# IWRL6432 register map
File version: 1.0
CPU: CM4 1.0, other endian, MPU, FPU, 3 interrupt priority bits
Registers are 32-bit, read-write, reset 0x0 unless marked. A register's access mark holds for its fields unless they carry their own. Offsets are from the block's base; [hi:lo] are bit positions; {n}, {i} and the like mark numbered series.

## APP_CTRL (part 2 of 2)
Base 0x56060000
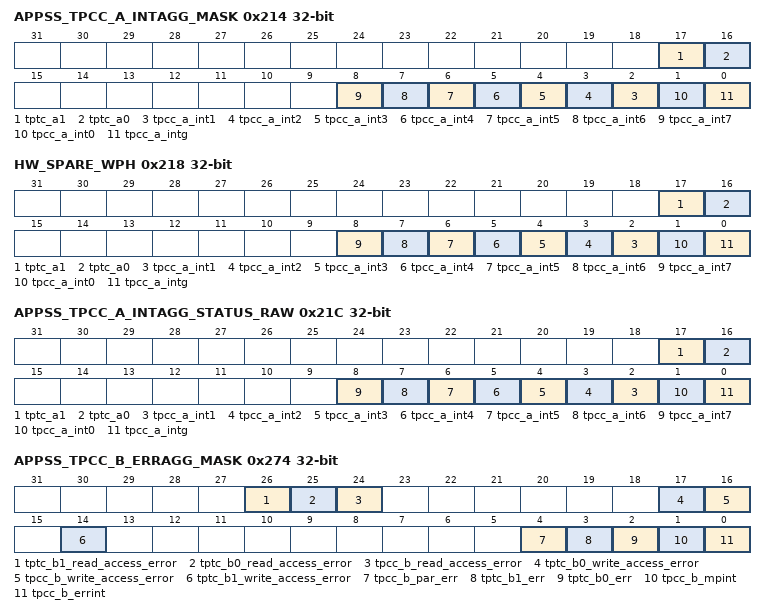
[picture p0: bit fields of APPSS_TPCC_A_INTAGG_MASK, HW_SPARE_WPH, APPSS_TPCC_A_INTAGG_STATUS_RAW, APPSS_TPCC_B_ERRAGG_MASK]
0x214 APPSS_TPCC_A_INTAGG_MASK
  [17] tptc_a1 — [17:17] Mask Interrupt from TPTC A1 to aggregated Interrupt TPCC_A_INTAGG 1 : Interrupt is Masked 0 : Interrupt is Unmasked
  [16] tptc_a0 — [16:16] Mask Interrupt from TPTC A0 to aggregated Interrupt TPCC_A_INTAGG 1 : Interrupt is Masked 0 : Interrupt is Unmasked
  [n+1] tpcc_a_int{n} (n=1..7) — [{n+1}:{n+1}] Mask Interrupt from TPCC_A to aggregated Interrupt TPCC_A_INTAGG 1 : Interrupt is Masked 0 : Interrupt is Unmasked
  [1] tpcc_a_int0 — [1:1] Mask Interrupt from TPCC A to aggregated Interrupt TPCC_A_INTAGG 1 : Interrupt is Masked 0 : Interrupt is Unmasked
  [0] tpcc_a_intg — [0:0] Mask Interrupt from TPCC_A to aggregated Interrupt TPCC_A_INTAGG 1 : Interrupt is Masked 0 : Interrupt is Unmasked
0x218 HW_SPARE_WPH
  [17] tptc_a1 — [17:17] Status of Interrupt from TPTC A1. Set only if Interupt is unmasked in TPCC_A_INTAGG_MASK Wrie 0x1 to clear this interrupt.
  [16] tptc_a0 — [16:16] Status of Interrupt from TPTC A0. Set only if Interupt is unmasked in TPCC_A_INTAGG_MASK Wrie 0x1 to clear this interrupt.
  [n+1] tpcc_a_int{n} (n=1..7) — [{n+1}:{n+1}] Status of Interrupt from TPCC_A. Set only if Interupt is unmasked in TPCC_A_INTAGG_MASK Wrie 0x1 to clear this interrupt.
  [1] tpcc_a_int0 — [1:1] Status of Interrupt from TPCC A Set only if Interupt is unmasked in TPCC_A_INTAGG_MASK Wrie 0x1 to clear this interrupt.
  [0] tpcc_a_intg — [0:0] Status of Interrupt from TPCC_A. Set only if Interupt is unmasked in TPCC_A_INTAGG_MASK Wrie 0x1 to clear this interrupt.
0x21C APPSS_TPCC_A_INTAGG_STATUS_RAW
  [17] tptc_a1 — [17:17] Raw Status of Interrupt from TPTC A1. Set irrespective if the Interupt is masked or unmasked in TPCC_A_INTAGG_MASK
  [16] tptc_a0 — [16:16] Raw Status of Interrupt from TPTC A0. Set irrespective if the Interupt is masked or unmasked in TPCC_A_INTAGG_MASK
  [n+1] tpcc_a_int{n} (n=1..7) — [{n+1}:{n+1}] Raw Status of Interrupt from TPCC_A. Set irrespective if the Interupt is masked or unmasked in TPCC_C_INTAGG_MASK
  [1] tpcc_a_int0 — [1:1] Raw Status of Interrupt from TPCC A. Set irrespective if the Interupt is masked or unmasked in TPCC_A_INTAGG_MASK
  [0] tpcc_a_intg — [0:0] Raw Status of Interrupt from TPCC_A. Set irrespective if the Interupt is masked or unmasked in TPCC_C_INTAGG_MASK
0x274 APPSS_TPCC_B_ERRAGG_MASK
  [26] tptc_b1_read_access_error — [26:26] Mask Error from TPTC_B0 to aggregated Error TPCC_B_ERRAGG 1 : Error is Masked 0 : Error is Unmasked
  [25] tptc_b0_read_access_error — [25:25] Mask Error from TPTC_B0 to aggregated Error TPCC_B_ERRAGG 1 : Error is Masked 0 : Error is Unmasked
  [24] tpcc_b_read_access_error — [24:24] Mask Error from TPCC_B to aggregated Error TPCC_B_ERRAGG 1 : Error is Masked 0 : Error is Unmasked
  [17] tptc_b0_write_access_error — [17:17] Mask Error from TPTC_B0 to aggregated Error TPCC_B_ERRAGG 1 : Error is Masked 0 : Error is Unmasked
  [16] tpcc_b_write_access_error — [16:16] Mask Error from TPCC_B to aggregated Error TPCC_B_ERRAGG 1 : Error is Masked 0 : Error is Unmasked
  [14] tptc_b1_write_access_error — [14:14] Mask Error from TPTC_B0 to aggregated Error TPCC_B_ERRAGG 1 : Error is Masked 0 : Error is Unmasked
  [4] tpcc_b_par_err — [4:4] Mask Error from TPCC_B to aggregated Error TPCC_B_ERRAGG 1 : Error is Masked 0 : Error is Unmasked
  [3] tptc_b1_err — [3:3] Mask Error from TPTC_B0 to aggregated Error TPCC_B_ERRAGG 1 : Error is Masked 0 : Error is Unmasked
  [2] tptc_b0_err — [2:2] Mask Error from TPTC_B0 to aggregated Error TPCC_B_ERRAGG 1 : Error is Masked 0 : Error is Unmasked
  [1] tpcc_b_mpint — [1:1] Mask Error from TPCC_B to aggregated Error TPCC_B_ERRAGG 1 : Error is Masked 0 : Error is Unmasked
  [0] tpcc_b_errint — [0:0] Mask Error from TPCC_B to aggregated Error TPCC_B_ERRAGG 1 : Error is Masked 0 : Error is Unmasked
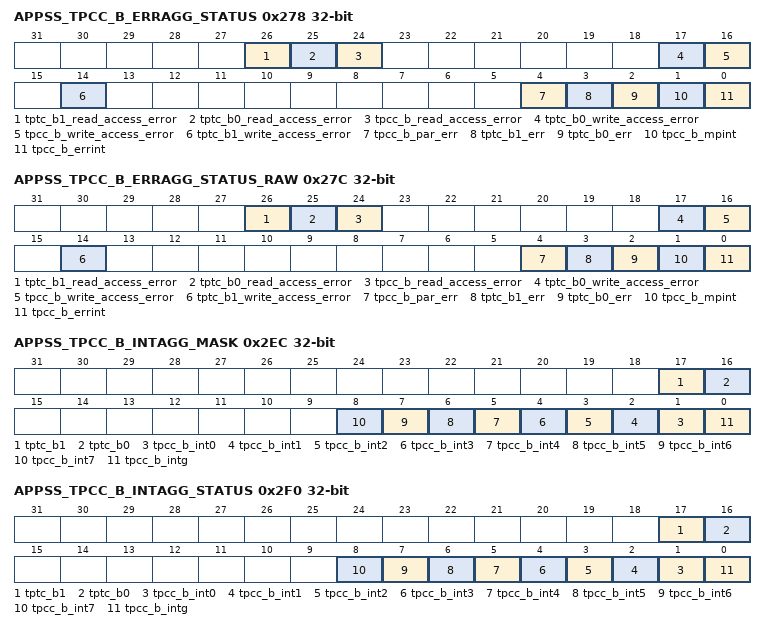
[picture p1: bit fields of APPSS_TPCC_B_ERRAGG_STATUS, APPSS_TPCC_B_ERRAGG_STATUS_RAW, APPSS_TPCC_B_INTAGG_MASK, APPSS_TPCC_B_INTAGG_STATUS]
0x278 APPSS_TPCC_B_ERRAGG_STATUS
  [26] tptc_b1_read_access_error — [26:26] Status of Error from TPTC_B0. Set only if Interupt is unmasked in TPCC_B_ERRAGG_MASK Wrie 0x1 to clear this Error.
  [25] tptc_b0_read_access_error — [25:25] Status of Error from TPTC_B0. Set only if Interupt is unmasked in TPCC_B_ERRAGG_MASK Wrie 0x1 to clear this Error.
  [24] tpcc_b_read_access_error — [24:24] Status of Error from TPCC_B. Set only if Interupt is unmasked in TPCC_B_ERRAGG_MASK Wrie 0x1 to clear this Error.
  [17] tptc_b0_write_access_error — [17:17] Status of Error from TPTC_B0. Set only if Interupt is unmasked in TPCC_B_ERRAGG_MASK Wrie 0x1 to clear this Error.
  [16] tpcc_b_write_access_error — [16:16] Status of Error from TPCC_B. Set only if Interupt is unmasked in TPCC_B_ERRAGG_MASK Wrie 0x1 to clear this Error.
  [14] tptc_b1_write_access_error — [14:14] Status of Error from TPTC_B0. Set only if Interupt is unmasked in TPCC_B_ERRAGG_MASK Wrie 0x1 to clear this Error.
  [4] tpcc_b_par_err — [4:4] Status of Error from TPCC_B. Set only if Interupt is unmasked in TPCC_B_ERRAGG_MASK Wrie 0x1 to clear this Error.
  [3] tptc_b1_err — [3:3] Status of Error from TPTC_B0. Set only if Interupt is unmasked in TPCC_B_ERRAGG_MASK Wrie 0x1 to clear this Error.
  [2] tptc_b0_err — [2:2] Status of Error from TPTC_B0. Set only if Interupt is unmasked in TPCC_B_ERRAGG_MASK Wrie 0x1 to clear this Error.
  [1] tpcc_b_mpint — [1:1] Status of Error from TPCC_B. Set only if Interupt is unmasked in TPCC_B_ERRAGG_MASK Wrie 0x1 to clear this Error.
  [0] tpcc_b_errint — [0:0] Status of Error from TPCC_B. Set only if Interupt is unmasked in TPCC_B_ERRAGG_MASK Wrie 0x1 to clear this Error.
0x27C APPSS_TPCC_B_ERRAGG_STATUS_RAW
  [26] tptc_b1_read_access_error — [26:26] Raw Status of Error from TPTC_B0. Set irrespective if the Interupt is masked or unmasked in TPCC_B_ERRAGG_MASK
  [25] tptc_b0_read_access_error — [25:25] Raw Status of Error from TPTC_B0. Set irrespective if the Interupt is masked or unmasked in TPCC_B_ERRAGG_MASK
  [24] tpcc_b_read_access_error — [24:24] Raw Status of Error from TPCC_B. Set irrespective if the Interupt is masked or unmasked in TPCC_B_ERRAGG_MASK
  [17] tptc_b0_write_access_error — [17:17] Raw Status of Error from TPTC_B0. Set irrespective if the Interupt is masked or unmasked in TPCC_B_ERRAGG_MASK
  [16] tpcc_b_write_access_error — [16:16] Raw Status of Error from TPCC_B. Set irrespective if the Interupt is masked or unmasked in TPCC_B_ERRAGG_MASK
  [14] tptc_b1_write_access_error — [14:14] Raw Status of Error from TPTC_B0. Set irrespective if the Interupt is masked or unmasked in TPCC_B_ERRAGG_MASK
  [4] tpcc_b_par_err — [4:4] Raw Status of Error from TPCC_B. Set irrespective if the Interupt is masked or unmasked in TPCC_B_ERRAGG_MASK
  [3] tptc_b1_err — [3:3] Raw Status of Error from TPTC_B0. Set irrespective if the Interupt is masked or unmasked in TPCC_B_ERRAGG_MASK
  [2] tptc_b0_err — [2:2] Raw Status of Error from TPTC_B0. Set irrespective if the Interupt is masked or unmasked in TPCC_B_ERRAGG_MASK
  [1] tpcc_b_mpint — [1:1] Raw Status of Error from TPCC_B. Set irrespective if the Interupt is masked or unmasked in TPCC_B_ERRAGG_MASK
  [0] tpcc_b_errint — [0:0] Raw Status of Error from TPCC_B. Set irrespective if the Interupt is masked or unmasked in TPCC_B_ERRAGG_MASK
0x2EC APPSS_TPCC_B_INTAGG_MASK
  [17] tptc_b1 — [17:17] Mask Interrupt from TPTC A0 to aggregated Interrupt TPCC_A_INTAGG 1 : Interrupt is Masked 0 : Interrupt is Unmasked
  [16] tptc_b0 — [16:16] Mask Interrupt from TPTC A0 to aggregated Interrupt TPCC_A_INTAGG 1 : Interrupt is Masked 0 : Interrupt is Unmasked
  [n+1] tpcc_b_int{n} (n=0..7) — [{n+1}:{n+1}] Mask Interrupt from TPCC_B to aggregated Interrupt TPCC_B_INTAGG 1 : Interrupt is Masked 0 : Interrupt is Unmasked
  [0] tpcc_b_intg — [0:0] Mask Interrupt from TPCC_B to aggregated Interrupt TPCC_B_INTAGG 1 : Interrupt is Masked 0 : Interrupt is Unmasked
0x2F0 APPSS_TPCC_B_INTAGG_STATUS
  [17] tptc_b1 — [17:17] Status of Interrupt from TPTC A0. Set only if Interupt is unmasked in TPCC_A_INTAGG_MASK Wrie 0x1 to clear this interrupt.
  [16] tptc_b0 — [16:16] Status of Interrupt from TPTC A0. Set only if Interupt is unmasked in TPCC_A_INTAGG_MASK Wrie 0x1 to clear this interrupt.
  [n+1] tpcc_b_int{n} (n=0..7) — [{n+1}:{n+1}] Status of Interrupt from TPCC_B. Set only if Interupt is unmasked in TPCC_B_INTAGG_MASK Wrie 0x1 to clear this interrupt.
  [0] tpcc_b_intg — [0:0] Status of Interrupt from TPCC_B. Set only if Interupt is unmasked in TPCC_B_INTAGG_MASK Wrie 0x1 to clear this interrupt.
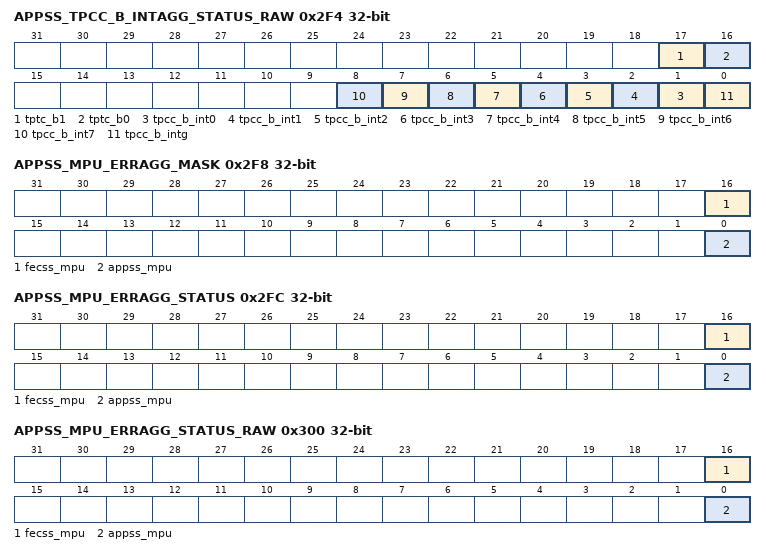
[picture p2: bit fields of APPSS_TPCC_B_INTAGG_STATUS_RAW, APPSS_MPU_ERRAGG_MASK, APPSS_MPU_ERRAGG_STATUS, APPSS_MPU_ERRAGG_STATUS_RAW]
0x2F4 APPSS_TPCC_B_INTAGG_STATUS_RAW
  [17] tptc_b1 — [17:17] Raw Status of Interrupt from TPTC A0. Set irrespective if the Interupt is masked or unmasked in TPCC_A_INTAGG_MASK
  [16] tptc_b0 — [16:16] Raw Status of Interrupt from TPTC A0. Set irrespective if the Interupt is masked or unmasked in TPCC_A_INTAGG_MASK
  [n+1] tpcc_b_int{n} (n=0..7) — [{n+1}:{n+1}] Raw Status of Interrupt from TPCC_B. Set irrespective if the Interupt is masked or unmasked in TPCC_C_INTAGG_MASK
  [0] tpcc_b_intg — [0:0] Raw Status of Interrupt from TPCC_B. Set irrespective if the Interupt is masked or unmasked in TPCC_C_INTAGG_MASK
0x2F8 APPSS_MPU_ERRAGG_MASK
  [16] fecss_mpu — [16:16] Mask Interrupt from FECSS MPU to aggregated Interrupt MPU_PROT_AGG_ERR 1 : Interrupt is Masked 0 : Interrupt is Unmasked
  [0] appss_mpu — [0:0] Mask Interrupt from APSS MPU to aggregated Interrupt MPU_PROT_AGG_ERR 1 : Interrupt is Masked 0 : Interrupt is Unmasked
0x2FC APPSS_MPU_ERRAGG_STATUS
  [16] fecss_mpu — [16:16] Status of Interrupt from FECSS MPU. Set only if Interupt is unmasked in APPSS_MPU_ERRAGG_MASK Wrie 0x1 to clear this interrupt.
  [0] appss_mpu — [0:0] Status of Interrupt from APSS MPU. Set only if Interupt is unmasked in APPSS_MPU_ERRAGG_MASK Wrie 0x1 to clear this interrupt.
0x300 APPSS_MPU_ERRAGG_STATUS_RAW
  [16] fecss_mpu — [16:16] Raw Status of FECSS MPU PROT ERR. Set irrespective if the Interupt is masked or unmasked in APPSS_MPU_ERRAGG_MASK
  [0] appss_mpu — [0:0] Raw Status of Interrupt from APSS MPU PROT ERR Set irrespective if the Interupt is masked or unmasked in APPSS_MPU_ERRAGG_MASK
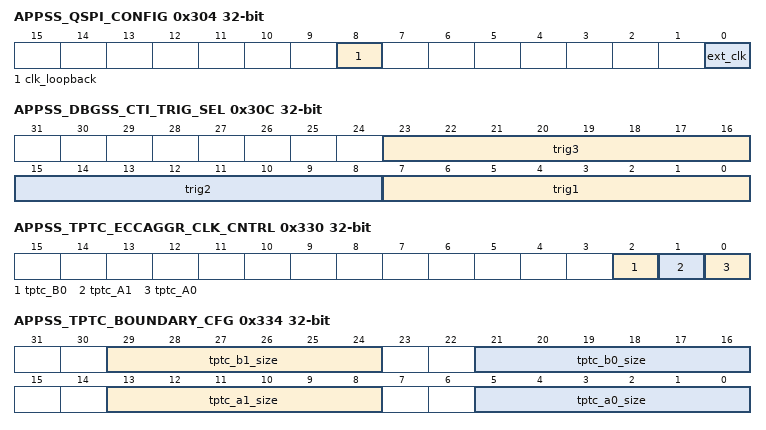
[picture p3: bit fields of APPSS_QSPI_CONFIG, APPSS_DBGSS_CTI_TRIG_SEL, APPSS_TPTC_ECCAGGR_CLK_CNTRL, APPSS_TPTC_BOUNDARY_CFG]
0x304 APPSS_QSPI_CONFIG
  [8] clk_loopback — [8:8] Reserved
  [0] ext_clk — [0:0] Reserved
0x308 APPSS_CTI_TRIG_SEL
  [7:0] trig8_sel — [7:0] Used for selecting the trigger source for 8th trigger of CTI
0x30C APPSS_DBGSS_CTI_TRIG_SEL
  [23:16] trig3 — [23:16] Reserved
  [15:8] trig2 — [15:8] Reserved
  [7:0] trig1 — [7:0] Reserved
{0x310+4i} APPSS_BOOT_INFO_REG{i} (i=0..7)
  [31:0] config — [31:0] Reserved Register for Software use
0x330 APPSS_TPTC_ECCAGGR_CLK_CNTRL
  [2] tptc_B0 — [2:2] Writing '0' will gate the clock to TPTC_B0-FIFO during ECC-AGGR interaction(fault injection)
  [1] tptc_A1 — [1:1] Writing '0' will gate the clock to TPTC_A1-FIFO during ECC-AGGR interaction(fault injection)
  [0] tptc_A0 — [0:0] Writing '0' will gate the clock to TPTC_A0-FIFO during ECC-AGGR interaction(fault injection)
0x334 APPSS_TPTC_BOUNDARY_CFG
  [29:24] tptc_b1_size — [29:24] 6 bit signal used for deciding the boundary crossing size for CID-RID-SID reordering of TPTC_B1 Example: writing 6'd19 decidies boundary to be 2^19 i.e. 512 KB
  [21:16] tptc_b0_size — [21:16] 6 bit signal used for deciding the boundary crossing size for CID-RID-SID reordering of TPTC_B0 Example: writing 6'd19 decidies boundary to be 2^19 i.e. 512 KB
  [13:8] tptc_a1_size — [13:8] 6 bit signal used for deciding the boundary crossing size for CID-RID-SID reordering of TPTC_A1 Example: writing 6'd19 decidies boundary to be 2^19 i.e. 512 KB
  [5:0] tptc_a0_size — [5:0] 6 bit signal used for deciding the boundary crossing size for CID-RID-SID reordering of TPTC_A0 Example: writing 6'd19 decidies boundary to be 2^19 i.e. 512 KB
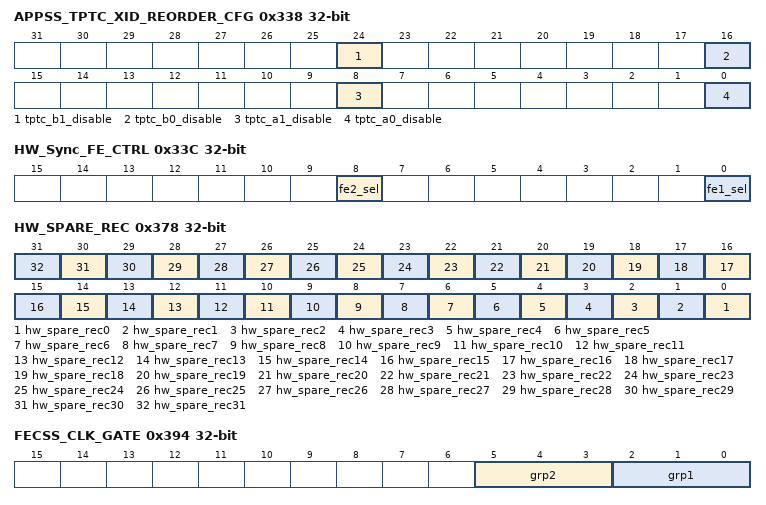
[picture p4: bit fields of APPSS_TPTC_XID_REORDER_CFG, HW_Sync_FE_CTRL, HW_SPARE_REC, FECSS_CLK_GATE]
0x338 APPSS_TPTC_XID_REORDER_CFG
  [24] tptc_b1_disable — [24:24] writing 1'b1 will disable the CID-RID-SID reodering feature for TPTC_B1
  [16] tptc_b0_disable — [16:16] writing 1'b1 will disable the CID-RID-SID reodering feature for TPTC_B0
  [8] tptc_a1_disable — [8:8] writing 1'b1 will disable the CID-RID-SID reodering feature for TPTC_A1
  [0] tptc_a0_disable — [0:0] writing 1'b1 will disable the CID-RID-SID reodering feature for TPTC_A0
0x33C HW_Sync_FE_CTRL
  [8] fe2_sel — [8:8] RESERVED
  [0] fe1_sel — [0:0] RESERVED
{0x33C+4i} HW_SPARE_REG{i} (i=1..3)
  [31:0] NU — [31:0] Resereved for R&D
0x34C NERROR_MASK
  [0] mask — [0:0] writing 1'b1 will mask the Nerror propagation to pad Writing 1'b0 will unmask the Nerror propagation to pad
0x350 HW_SPARE_RW0
  [31:0] hw_spare_rw0 — [31:0] Bit 0: Writing 1'b1 will mask the hwa local ram agg serr propagation to ESM Writing 1'b0 will unmask the hwa local ram agg serr propagation to ESM Bit 1 : Writing 1'b1 will mask the hwa local ram agg uerr propagation to ESM Writing 1'b0 will unmask the hwa local ram agg uerr propagation to ESM Bit 2 to 31 Reserved
{0x350+4i} HW_SPARE_RW{i} (i=1..5)
  [31:0] hw_spare_rw{i} — [31:0] Reserved for HW R&D
{0x368+4i} HW_SPARE_RO{i} (i=0..3)
  [31:0] hw_spare_ro{i} — [31:0] Reserved for HW R&D
0x378 HW_SPARE_REC
  [n] hw_spare_rec{n} (n=0..31) — [{n}:{n}] Reserved for HW R&D
0x37C APP_CTRL
  [0] ecc_disable_2k_ram — [0:0] Reserved
0x380 WIC_CTRL
  [31:0] wicmask — [31:0] 1 => The corresponding interrupt is Masked (interrupt will not be generated) 0 => The corresponding interrupt is UnMasked (interrupt will be generated) 0 : ESM_HI_IRQ (NMI) 1 : ESM_LO_IRQ (INT#1) 2 : FECSS_FRAMETIMER_FRAME_START (INT#33) 3 : MUXED_FECSS_FRAME_START_OFFSET_INTR_TIME1 (INT#35) 4 : FECSS_FRAME_START_OFFSET_INTR_TIME2 (INT#36) 5 : FECSS_FRAME_START_OFFSET_INTR_TIME3 (INT#37) 6 : FECSS_BURST_START_OFFSET_TIME(INT#38) 7 : MUXED_APPSS_RTI1_RTI2_INT_REQ0(INT#43) 8 : MUXED_APPSS_RTI1_RTI2_INT_REQ1(INT#44) 9 : MUXED_APPSS_RTI1_RTI2_INT_REQ2(INT#45) 10 : MUXED_APPSS_RTI1_RTI2_INT_REQ3(INT#46) 11 : APPSS_SPI_IRQ_REQ(INT#14) 12 : SPI2_IRQ_REQ (part of INT#28) 13 : APPSS_LIN_INT0 (INT#10) 14 : APPSS_LIN_INT0 (INT#11) 15 : APPSS_MCAN_INT0(INT#21) 16 : APPSS_MCAN_INT1(INT#22) 17 : APPSS_SCI2_INT0(INT#62) 18 : APPSS_SCI2_INT0(INT#63) 19 : APPSS_SPI_IRQ_REQ(INT#14) 20 : SPI2_IRQ_REQ (part of INT#28) 21 : APPSS_LIN_INT0 (INT#10) 22 : APPSS_LIN_INT0 (INT#11) 23 : APPSS_MCAN_INT0(INT#21) 24 : APPSS_MCAN_INT1(INT#22) 25 : APPSS_SCI2_INT0(INT#62) 26 : APPSS_SCI2_INT0(INT#63) 27 : SYNC_IN 28 : RADAR_DEVICESLEEP_WAKEUP_INTERRUPT 29 to 31 : Reserved
0x384 WIC_STAT_CLR
  [31:0] wicstatclr — [31:0] 1 => Writing 1 to this bit, will clear the WIC_STAT status register of the corresponding bit. Self-clearing 0 => Writing 0 to this bit, leavesWIC_STAT status register unchanged for the corresponding bit.
0x388 WIC_STAT
  [31:0] wicstat — [31:0] 1 => Interrupt bit set. The interupt bit is sticky bit. Should be cleared using WIC_STAT_CLR register or subsystem reset. 0 -> Interrupt bit not set. Sticky bits keep their value when they changed to logical 1 and is cleared only by writing 1 to WIC_STAT_CLR register.
0x38C WICEN
  [0] wicen — [0:0] 1 :> Wakeup Interrupt Controller (WIC) of CM4 is Enabled 0 :> Disabled
0x390 FORCEFCLKACTIVE
  [0] forcefclkactive — [0:0] 1 :> Forces FCLK to be active and inhibits CM4 Entering CPU DeepSleep mode 0 :> Allows gating of FCLK based on CPU DEEPSLEEP entry mechanism
0x394 FECSS_CLK_GATE
  [5:3] grp2 — [5:3] Multibit: Writing 3'b111 will gate ADC_CLK going to DFE and Timing Engine
  [2:0] grp1 — [2:0] Multibit: Writing 3'b111 will gate FEC_SYS_CLK and FECSS peripheral clocks except DFE and Timing Engine
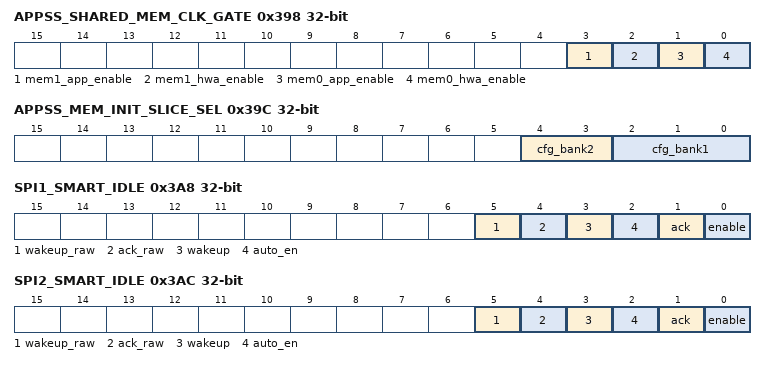
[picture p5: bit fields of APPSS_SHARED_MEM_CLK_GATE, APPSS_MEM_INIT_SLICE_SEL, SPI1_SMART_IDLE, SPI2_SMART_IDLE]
0x398 APPSS_SHARED_MEM_CLK_GATE
  [3] mem1_app_enable — [3:3] 1'b1 : Enable APP CLK ICG for second 128KB of shared mem 1'b0 : Disable APP CLK ICG for second 128 KB of shared mem
  [2] mem1_hwa_enable — [2:2] 1'b1 : Enable HWA CLK ICG for second 128 KB of shared mem 1'b0 : Disable HWA CLK ICG for second 128 KB of shared mem
  [1] mem0_app_enable — [1:1] 1'b1 : Enable APP CLK ICG for first 128KB of shared mem 1'b0 : Disable APP CLK ICG for first 128 KB of shared mem
  [0] mem0_hwa_enable — [0:0] 1'b1 : Enable HWA CLK ICG for first 128 KB of shared mem 1'b0 : Disable HWA CLK ICG for first 128 KB of shared mem
0x39C APPSS_MEM_INIT_SLICE_SEL
  [4:3] cfg_bank2 — [4:3] Selects the APPSS RAM2 partition that needs to be initialized. More than 1 partitions can be selected for mem_init. Bit#0 : Selects RAM_2A (16KB) Bit#1 : Selects RAM_2B (112KB) 1 => RAM partition selected for mem_init operation 0 => RAM partition not selected for mem_init operation.
  [2:0] cfg_bank1 — [2:0] Selects the APPSS RAM1 partition that needs to be initialized. More than 1 partitions can be selected for mem_init. Bit#0 : Selects RAM_1A (64KB) Bit#1 : Selects RAM_1B (64KB) Bit#2 : Selects RAM_1C (128KB) 1 => RAM selected for mem_init operation 0 => RAM not selected for mem_init operation.
0x3A0 APPSS_QSPI_CHAR_EXT_CLK_EN
  [0] enable — [0:0] Selects the QSPI system clock. Only for DFT purposes. This should not be changed for functional operation. 0 => QSPI_CLK from APPSS RCM 1 => SPI1_CLK from APPSS RCM
0x3A4 APPSS_QSPI_EXT_CLK_EN
  [0] enable — [0:0] Selects the QSPI interface clock. This register bit is used only for AC CHAR operation and not for functional usage. 0 => default QSPI IP clock return from PAD 1 => SPI1 IF CLK. (McSPI IF clock).
0x3A8 SPI1_SMART_IDLE
  [5] wakeup_raw — [5:5] Description: RAW status of CLKSTOP_WAKEUP from SPI1 module. This should be interpreted along with SPI1_SMART_IDLE_WAKEUP SPI1_SMART_IDLE_WAKEUP_RAW, SPI1_SMART_IDLE_WAKEUP 0 , 0 => WAKEUP is LOW from IP, and No pending WAKEUP status 0 , 1 => WAKEUP is LOW from IP, and pending WAKEUP status 1 , 0 => WAKEUP is HIGH from IP, and No pending WAKEUP status 1 , 1 => WAKEUP is HIGH from IP, and pending WAKEUP status
  [4] ack_raw — [4:4] Description: RAW status of CLKSTOP_ACK from McSPI (SPI1) module. This should be interpreted along with SPI1_SMART_IDLE_ACK SPI1_SMART_IDLE_ACK_RAW, SPI1_SMART_IDLE_ACK 0 , 0 => ACK is LOW from IP, and No pending ACK status 0 , 1 => ACK is LOW from IP, and pending ACK status 1 , 0 => ACK is HIGH from IP, and No pending ACK status 1 , 1 => ACK is HIGH from IP, and pending ACK status
  [3] wakeup — [3:3] This register reflects the Wakeup Status of the IP. The bit is sticky bit and the user is should clear once the status is read by write-1-to-clear.
  [2] auto_en — [2:2] It is used to select smart idle mode. 1 => Automatic mode - Entry to smart idle mode Is manual by setting SMART_IDLE_ENABLE = 1. When the wakeup Signal is asserted (based on the activity), The clkstop_req is pulled low automatically. 0 => Manual mode - The entry and exit to Smart Idle is user controlled based on polling SMART_IDLE_ACK and SMART_IDLE_WAKEUP
  [1] ack — [1:1] 1 => SPI1 in smart idle mode 0 => SPI1 not in smart idle mode The bit is sticky bit and the user is should clear once the status is read by write-1-to-clear.
  [0] enable — [0:0] 1 => Smart IDLE mode enabled. When set, request the clock gating of SPI1 module. 0 => Disable Smart IDLE mode for SPI1
0x3AC SPI2_SMART_IDLE
  [5] wakeup_raw — [5:5] Description: RAW status of CLKSTOP_WAKEUP from SPI2 module. This should be interpreted along with SPI2_SMART_IDLE_WAKEUP SPI2_SMART_IDLE_WAKEUP_RAW, SPI2_SMART_IDLE_WAKEUP 0 , 0 => WAKEUP is LOW from IP, and No pending WAKEUP status 0 , 1 => WAKEUP is LOW from IP, and pending WAKEUP status 1 , 0 => WAKEUP is HIGH from IP, and No pending WAKEUP status 1 , 1 => WAKEUP is HIGH from IP, and pending WAKEUP status
  [4] ack_raw — [4:4] Description: RAW status of CLKSTOP_ACK from McSPI (SPI2) module. This should be interpreted along with SPI2_SMART_IDLE_ACK SPI2_SMART_IDLE_ACK_RAW, SPI2_SMART_IDLE_ACK 0 , 0 => ACK is LOW from IP, and No pending ACK status 0 , 1 => ACK is LOW from IP, and pending ACK status 1 , 0 => ACK is HIGH from IP, and No pending ACK status 1 , 1 => ACK is HIGH from IP, and pending ACK status
  [3] wakeup — [3:3] This register reflects the Wakeup Status of the IP. The bit is sticky bit and the user is should clear once the status is read by write-1-to-clear.
  [2] auto_en — [2:2] It is used to select smart idle mode. 1 => Automatic mode - In this mode, entry to smart idle mode is manual by setting SMART_IDLE_ENABLE = 1. When the wakeup Signal is asserted (based on the activity), The clkstop_req is pulled low automatically. 0 => Manual mode - The entry and exit to Smart Idle is user controlled based on polling SMART_IDLE_ACK and SMART_IDLE_WAKEUP
  [1] ack — [1:1] 1 => SPI2 in smart idle mode 0 => SPI2 not in smart idle mode The bit is sticky bit and the user is should clear once the status is read by write-1-to-clear.
  [0] enable — [0:0] 1 => Smart IDLE mode enabled. When set, request the clock gating of SPI2 module. 0 => Disable Smart IDLE mode for SPI2
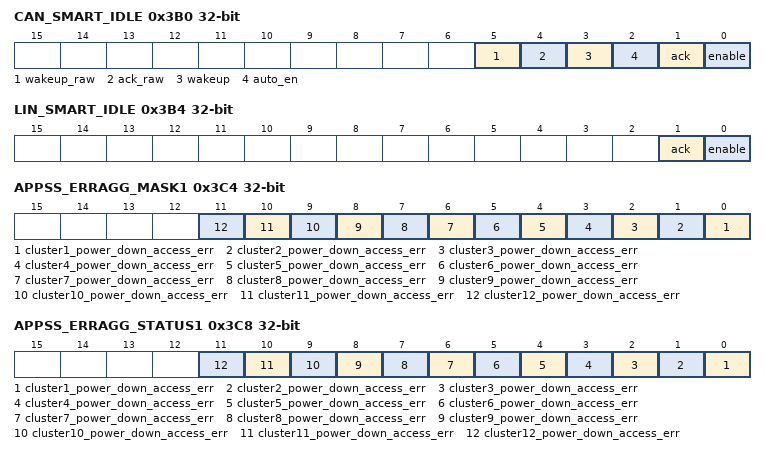
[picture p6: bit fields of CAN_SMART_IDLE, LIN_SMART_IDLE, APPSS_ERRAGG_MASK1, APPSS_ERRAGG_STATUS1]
0x3B0 CAN_SMART_IDLE
  [5] wakeup_raw — [5:5] Description: RAW status of CLKSTOP_WAKEUP from CANFD module. This should be interpreted along with CAN_SMART_IDLE_WAKEUP CAN_SMART_IDLE_WAKEUP_RAW, CAN_SMART_IDLE_WAKEUP 0 , 0 => WAKEUP is LOW from IP, and No pending WAKEUP status 0 , 1 => WAKEUP is LOW from IP, and pending WAKEUP status 1 , 0 => WAKEUP is HIGH from IP, and No pending WAKEUP status 1 , 1 => WAKEUP is HIGH from IP, and pending WAKEUP status
  [4] ack_raw — [4:4] Description: RAW status of CLKSTOP_ACK from CANFD module. This should be interpreted along with CAN_SMART_IDLE_ACK CAN_SMART_IDLE_ACK_RAW, CAN_SMART_IDLE_ACK 0 , 0 => ACK is LOW from IP, and No pending ACK status 0 , 1 => ACK is LOW from IP, and pending ACK status 1 , 0 => ACK is HIGH from IP, and No pending ACK status 1 , 1 => ACK is HIGH from IP, and pending ACK status
  [3] wakeup — [3:3] This register reflects the Wakeup Status of the IP. The bit is sticky bit and the user is should clear once the status is read by write-1-to-clear.
  [2] auto_en — [2:2] It is used to select smart idle mode. 1 => Automatic mode - In this mode, entry to smart idle mode is manual by setting SMART_IDLE_ENABLE = 1. When the wakeup Signal is asserted (based on the activity), The clkstop_req is pulled low automatically. 0 => Manual mode - The entry and exit to Smart Idle is user controlled based on polling SMART_IDLE_ACK and SMART_IDLE_WAKEUP
  [1] ack — [1:1] 1 => CAN in smart idle mode0 => CAN not in smart idle mode The bit is sticky bit and the user is should clear once the status is read by write-1-to-clear.
  [0] enable — [0:0] 1 => Smart IDLE mode enabled. When set, Request the clock gating of CAN module.0 => Disable Smart IDLE mode for CAN
0x3B4 LIN_SMART_IDLE
  [1] ack — [1:1] 1 => LIN in smart idle mode0 => LIN not in smart idle mode
  [0] enable — [0:0] 1 => Smart IDLE mode enabled. When set, Request the clock gating of LIN module.0 => Disable Smart IDLE mode for LIN
0x3B8 HWASS_CLK_GATE
  [2:0] enable — [2:0] RESERVED
0x3BC CFG_TIMEOUT_PCR3
  [31:0] value — [31:0] PCR3Timeout Value
0x3C4 APPSS_ERRAGG_MASK1
  [n-1] cluster{n}_power_down_access_err (n=1..12) — [{n-1}:{n-1}] Mask Interrupt from cluster{n}_power_down_access_err Interrupt APPSS_ACCESS_ERRAGG 1 : Interrupt is Masked 0 : Interrupt is Unmasked
0x3C8 APPSS_ERRAGG_STATUS1
  [n-1] cluster{n}_power_down_access_err (n=1..12) — [{n-1}:{n-1}] Status of Interrupt from cluster{n}_power_down_access_err Set only if Interupt is unmasked in APPSS_ERRAGG_MASK1 Wrie 0x1 to clear this interrupt.
0x3CC FORCEHCLKACTIVE
  [0] forcehclkactive — [0:0] 1 :> Gate HCLK 0 :> UnGate HCLK
{0x3C8+8i} APPSS_RAM{i}_OWRITE_ERR (i=1..3)
  [0] err — [0:0] RAM{i} ahb2sram write error - Sticky Bit
{0x3CC+8i} APPSS_RAM{i}_OWRITE_ERR_ADDR (i=1..3)
  [31:0] address — [31:0] RAM{i} ahb2sram write error Address
0x3E8 APPSS_SHRD_RAM_OWRITE_ERR
  [0] err — [0:0] SHARED RAM ahb2sram write error - Sticky Bit
0x3EC APPSS_SHRD_RAM_OWRITE_ERR_ADDR
  [31:0] address — [31:0] SHARED RAM ahb2sram write error Address
0x3F0 APPSS_OWRITE_ERR_AGGR
  [0] err — [0:0] Ored error of all write error signals -Sticky Bit
{0x3DC+4i} HW_SPARE_RW{i} (i=6..9)
  [31:0] hw_spare_rw{i} — [31:0] Reserved for HW R&D
0x404 HW_SPARE_HWA_RW0
  [31:0] hw_spare_hwa_rw0 — [31:0] Reserved for HW R&D
0x1008 LOCK0_KICK0 — - KICK0 component
  [31:0] KICK0_COMPONENT — [31:0] - KICK0 component
0x100C LOCK0_KICK1 — - KICK1 component
  [31:0] KICK1_COMPONENT — [31:0] - KICK1 component
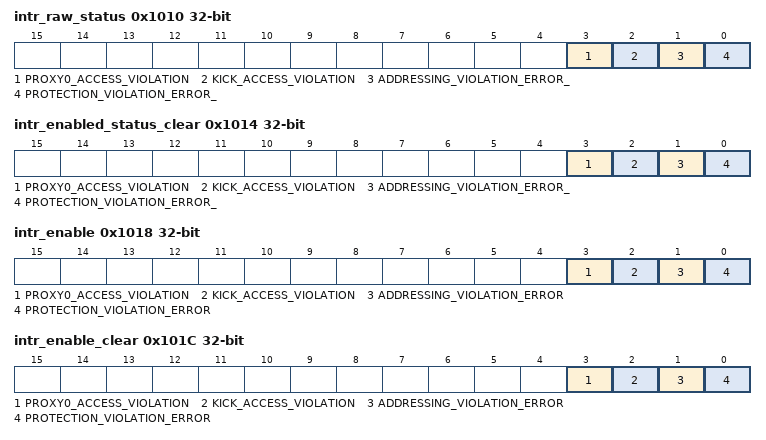
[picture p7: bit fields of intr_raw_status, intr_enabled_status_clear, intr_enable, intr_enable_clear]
0x1010 intr_raw_status — Interrupt Raw Status/Set Register
  [3] PROXY0_ACCESS_VIOLATION — [3:3] Proxy0 access violation error. Raw status is read. Write a 1 to set the status. Writing a 0 has no effect.
  [2] KICK_ACCESS_VIOLATION — [2:2] Kick access violation error. Raw status is read. Write a 1 to set the status. Writing a 0 has no effect.
  [1] ADDRESSING_VIOLATION_ERROR_ — [1:1] Addressing violation error. Raw status is read. Write a 1 to set the status. Writing a 0 has no effect.
  [0] PROTECTION_VIOLATION_ERROR_ — [0:0] Protection violation error. Raw status is read. Write a 1 to set the status. Writing a 0 has no effect.
0x1014 intr_enabled_status_clear — Interrupt Enabled Status/Clear register
  [3] PROXY0_ACCESS_VIOLATION — [3:3] Proxy0 access violation error. Enabled status is read. Write a 1 to clear the status. Writing a 0 has no effect.
  [2] KICK_ACCESS_VIOLATION — [2:2] Kick access violation error. Enabled status is read. Write a 1 to clear the status. Writing a 0 has no effect.
  [1] ADDRESSING_VIOLATION_ERROR_ — [1:1] Addressing violation error. Enabled status is read. Write a 1 to clear the status. Writing a 0 has no effect.
  [0] PROTECTION_VIOLATION_ERROR_ — [0:0] Protection violation error. Enabled status is read. Write a 1 to clear the status. Writing a 0 has no effect.
0x1018 intr_enable — Interrupt Enable register
  [3] PROXY0_ACCESS_VIOLATION — [3:3] Proxy0 access violation error enable. Write a 1 to set the enable. Writing a 0 has no effect.
  [2] KICK_ACCESS_VIOLATION — [2:2] Kick access violation error enable. Write a 1 to set the enable. Writing a 0 has no effect.
  [1] ADDRESSING_VIOLATION_ERROR — [1:1] Addressing violation error enable. Write a 1 to set the enable. Writing a 0 has no effect.
  [0] PROTECTION_VIOLATION_ERROR — [0:0] Protection violation error enable. Write a 1 to set the enable. Writing a 0 has no effect.
0x101C intr_enable_clear — Interrupt Enable Clear register
  [3] PROXY0_ACCESS_VIOLATION — [3:3] Proxy0 access violation error enable clear. Write a 1 to clear the enable. Writing a 0 has no effect.
  [2] KICK_ACCESS_VIOLATION — [2:2] Kick access violation error enable clear. Write a 1 to clear the enable. Writing a 0 has no effect.
  [1] ADDRESSING_VIOLATION_ERROR — [1:1] Addressing violation error enable clear. Write a 1 to clear the enable. Writing a 0 has no effect.
  [0] PROTECTION_VIOLATION_ERROR — [0:0] Protection violation error enable clear. Write a 1 to clear the enable. Writing a 0 has no effect.
0x1020 eoi
  [7:0] EOI_VECTOR_VALUE_ — [7:0] EOI vector value. Write this with interrupt distribution value in the chip.
0x1024 fault_address
  [31:0] FAULT_ADDRESS_ — [31:0] Fault Address.
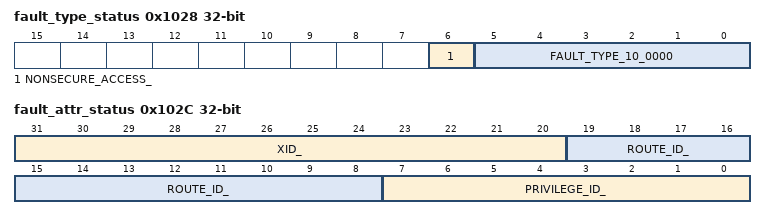
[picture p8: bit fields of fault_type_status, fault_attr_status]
0x1028 fault_type_status
  [6] NONSECURE_ACCESS_ — [6:6] Non-secure access.
  [5:0] FAULT_TYPE_10_0000 — [5:0] Fault Type 10_0000 = Supervisor read fault - priv = 1 dir = 1 dtype != 1 01_0000 = Supervisor write fault - priv = 1 dir = 0 00_1000 = Supervisor execute fault - priv = 1 dir = 1 dtype = 1 00_0100 = User read fault - priv = 0 dir = 1 dtype = 1 00_0010 = User write fault - priv = 0 dir = 0 00_0001 = User execute fault - priv = 0 dir = 1 dtype = 1 00_0000 = No fault
0x102C fault_attr_status — Fault Attribute Status register
  [31:20] XID_ — [31:20] XID.
  [19:8] ROUTE_ID_ — [19:8] Route ID.
  [7:0] PRIVILEGE_ID_ — [7:0] Privilege ID.
0x1030 fault_clear
  [0] FAULT_CLEAR__WRITING — [0:0] Fault clear. Writing a 1 clears the current fault. Writing a 0 has no effect.
